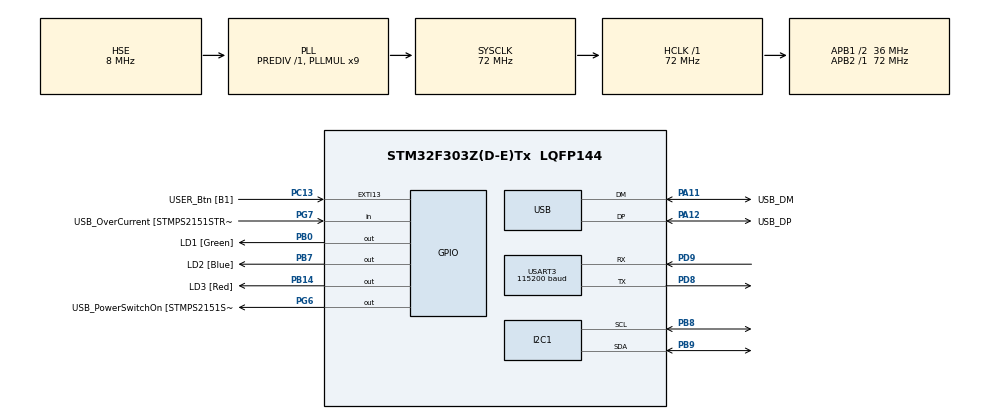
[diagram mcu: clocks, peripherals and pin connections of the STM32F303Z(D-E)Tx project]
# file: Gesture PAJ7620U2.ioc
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Mcu.Family=STM32F3
RCC.CortexFreq_Value=72000000
PG6.Signal=GPIO_Output
PB14.GPIO_Label=LD3 [Red]
PG6.GPIO_Label=USB_PowerSwitchOn [STMPS2151STR_EN]
PA14.GPIO_Label=TCK
RCC.SYSCLKSourceVirtual=RCC_SYSCLKSOURCE_PLLCLK
VP_RTC_VS_RTC_Activate.Mode=RTC_Enabled
PA11.Mode=Device
PB0.GPIO_Label=LD1 [Green]
PC13.GPIO_Label=USER_Btn [B1]
PD9.Mode=Asynchronous
ProjectManager.StackSize=0x400
USART3.VirtualMode-Asynchronous=VM_ASYNC
PA12.Signal=USB_DP
USART3.BaudRate=115200
RCC.HCLKFreq_Value=72000000
RCC.APB2TimFreq_Value=72000000
PD8.Signal=USART3_TX
RCC.AHBFreq_Value=72000000
RCC.HSE_VALUE=8000000
PF0-OSC_IN.GPIO_Label=MCO [STM32F103CBT6_PA8]
RCC.PLLMUL=RCC_PLL_MUL9
PC14-OSC32_IN.Mode=LSE-External-Oscillator
PA14.Mode=Serial_Wire
PB7.Signal=GPIO_Output
PB7.GPIO_Label=LD2 [Blue]
Mcu.Package=LQFP144
PB9.Signal=I2C1_SDA
RCC.APB1TimFreq_Value=72000000
PB3.GPIO_Label=SWO
PC15-OSC32_OUT.Mode=LSE-External-Oscillator
PG7.Signal=GPIO_Input
PC13.Signal=GPXTI13
NVIC.USB_LP_CAN_RX0_IRQn=true\:0\:0\:false\:false\:true\:true\:true
PA11.GPIO_Label=USB_DM
PD9.Signal=USART3_RX
RCC.APB1CLKDivider=RCC_HCLK_DIV2
PC14-OSC32_IN.Signal=RCC_OSC32_IN
PA12.GPIO_Label=USB_DP
PA13.Signal=SYS_JTMS-SWDIO
ProjectManager.TargetToolchain=STM32CubeIDE
PB9.Mode=I2C
RCC.USBFreq_Value=48000000
PC15-OSC32_OUT.Signal=RCC_OSC32_OUT
PD8.Mode=Asynchronous
PF0-OSC_IN.Mode=HSE-External-Clock-Source
PB14.Signal=GPIO_Output
board=NUCLEO-F303ZE
RCC.APB2Freq_Value=72000000
RCC.PRESCALERUSB=RCC_USBCLKSOURCE_PLL_DIV1_5
PG7.GPIO_Label=USB_OverCurrent [STMPS2151STR_FAULT]
PA13.Mode=Serial_Wire
Mcu.Name=STM32F303Z(D-E)Tx
PA13.GPIO_Label=TMS
I2C1.OwnAddress=0x73
PB3.Signal=SYS_JTDO-TRACESWO
RCC.SYSCLKFreq_VALUE=72000000
PA12.Mode=Device
PA11.Signal=USB_DM
PA14.Signal=SYS_JTCK-SWCLK
ProjectManager.HeapSize=0x200
RCC.HSI_VALUE=8000000
NVIC.PriorityGroup=NVIC_PRIORITYGROUP_4
PB8.Mode=I2C
PB8.Signal=I2C1_SCL
PF0-OSC_IN.Signal=RCC_OSC_IN
RCC.APB1Freq_Value=36000000
PB0.Signal=GPIO_Output

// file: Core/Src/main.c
/* USER CODE BEGIN Header */
/**
  ******************************************************************************
  * @file           : main.c
  * @brief          : Main program body
  ******************************************************************************
  * @attention
  *
  * <h2><center>&copy; Copyright (c) 2021 STMicroelectronics.
  * All rights reserved.</center></h2>
  *
  * This software component is licensed by ST under BSD 3-Clause license,
  * the "License"; You may not use this file except in compliance with the
  * License. You may obtain a copy of the License at:
  *                        opensource.org/licenses/BSD-3-Clause
  *
  ******************************************************************************
  */
/* USER CODE END Header */
#include "main.h"

/* USER CODE BEGIN Includes */
#include "GESTURE.h"

/* USER CODE END Includes */

I2C_HandleTypeDef hi2c1;

RTC_HandleTypeDef hrtc;

UART_HandleTypeDef huart3;

PCD_HandleTypeDef hpcd_USB_FS;

void SystemClock_Config(void);
static void MX_GPIO_Init(void);
static void MX_RTC_Init(void);
static void MX_USB_PCD_Init(void);
static void MX_I2C1_Init(void);
static void MX_USART3_UART_Init(void);

int main(void)
{

  /* MCU Configuration--------------------------------------------------------*/

  /* Reset of all peripherals, Initializes the Flash interface and the Systick. */
  HAL_Init();

  /* Configure the system clock */
  SystemClock_Config();

  /* Initialize all configured peripherals */
  MX_GPIO_Init();
  MX_RTC_Init();
  MX_USB_PCD_Init();
  MX_I2C1_Init();
  MX_USART3_UART_Init();

  /* Infinite loop */
  /* USER CODE BEGIN WHILE */
  while (1)
  {
	  /* HAL_Delay(700); */
	 /*  initializeRegisters(); */
	 /*  GESTURE_Actions(); */
    /* USER CODE END WHILE */

    /* USER CODE BEGIN 3 */
	  HAL_Delay(700);
	  GESTURE_Actions();
  }
  /* USER CODE END 3 */
}

void SystemClock_Config(void)
{
  RCC_OscInitTypeDef RCC_OscInitStruct = {0};
  RCC_ClkInitTypeDef RCC_ClkInitStruct = {0};
  RCC_PeriphCLKInitTypeDef PeriphClkInit = {0};

  /** Initializes the RCC Oscillators according to the specified parameters
  * in the RCC_OscInitTypeDef structure.
  */
  RCC_OscInitStruct.OscillatorType = RCC_OSCILLATORTYPE_HSI|RCC_OSCILLATORTYPE_LSI
                              |RCC_OSCILLATORTYPE_HSE;
  RCC_OscInitStruct.HSEState = RCC_HSE_BYPASS;
  RCC_OscInitStruct.HSIState = RCC_HSI_ON;
  RCC_OscInitStruct.HSICalibrationValue = RCC_HSICALIBRATION_DEFAULT;
  RCC_OscInitStruct.LSIState = RCC_LSI_ON;
  RCC_OscInitStruct.PLL.PLLState = RCC_PLL_ON;
  RCC_OscInitStruct.PLL.PLLSource = RCC_PLLSOURCE_HSE;
  RCC_OscInitStruct.PLL.PLLMUL = RCC_PLL_MUL9;
  RCC_OscInitStruct.PLL.PREDIV = RCC_PREDIV_DIV1;
  if (HAL_RCC_OscConfig(&RCC_OscInitStruct) != HAL_OK)
  {
    Error_Handler();
  }
  /** Initializes the CPU, AHB and APB buses clocks
  */
  RCC_ClkInitStruct.ClockType = RCC_CLOCKTYPE_HCLK|RCC_CLOCKTYPE_SYSCLK
                              |RCC_CLOCKTYPE_PCLK1|RCC_CLOCKTYPE_PCLK2;
  RCC_ClkInitStruct.SYSCLKSource = RCC_SYSCLKSOURCE_PLLCLK;
  RCC_ClkInitStruct.AHBCLKDivider = RCC_SYSCLK_DIV1;
  RCC_ClkInitStruct.APB1CLKDivider = RCC_HCLK_DIV2;
  RCC_ClkInitStruct.APB2CLKDivider = RCC_HCLK_DIV1;

  if (HAL_RCC_ClockConfig(&RCC_ClkInitStruct, FLASH_LATENCY_2) != HAL_OK)
  {
    Error_Handler();
  }
  PeriphClkInit.PeriphClockSelection = RCC_PERIPHCLK_USB|RCC_PERIPHCLK_USART3
                              |RCC_PERIPHCLK_I2C1|RCC_PERIPHCLK_RTC;
  PeriphClkInit.Usart3ClockSelection = RCC_USART3CLKSOURCE_PCLK1;
  PeriphClkInit.I2c1ClockSelection = RCC_I2C1CLKSOURCE_HSI;
  PeriphClkInit.RTCClockSelection = RCC_RTCCLKSOURCE_LSI;
  PeriphClkInit.USBClockSelection = RCC_USBCLKSOURCE_PLL_DIV1_5;
  if (HAL_RCCEx_PeriphCLKConfig(&PeriphClkInit) != HAL_OK)
  {
    Error_Handler();
  }
}

static void MX_I2C1_Init(void)
{

  hi2c1.Instance = I2C1;
  hi2c1.Init.Timing = 0x2000090E;
  hi2c1.Init.OwnAddress1 = 230;
  hi2c1.Init.AddressingMode = I2C_ADDRESSINGMODE_7BIT;
  hi2c1.Init.DualAddressMode = I2C_DUALADDRESS_DISABLE;
  hi2c1.Init.OwnAddress2 = 0;
  hi2c1.Init.OwnAddress2Masks = I2C_OA2_NOMASK;
  hi2c1.Init.GeneralCallMode = I2C_GENERALCALL_DISABLE;
  hi2c1.Init.NoStretchMode = I2C_NOSTRETCH_DISABLE;
  if (HAL_I2C_Init(&hi2c1) != HAL_OK)
  {
    Error_Handler();
  }
  /** Configure Analogue filter
  */
  if (HAL_I2CEx_ConfigAnalogFilter(&hi2c1, I2C_ANALOGFILTER_ENABLE) != HAL_OK)
  {
    Error_Handler();
  }
  /** Configure Digital filter
  */
  if (HAL_I2CEx_ConfigDigitalFilter(&hi2c1, 0) != HAL_OK)
  {
    Error_Handler();
  }

}

static void MX_RTC_Init(void)
{

  /** Initialize RTC Only
  */
  hrtc.Instance = RTC;
  hrtc.Init.HourFormat = RTC_HOURFORMAT_24;
  hrtc.Init.AsynchPrediv = 127;
  hrtc.Init.SynchPrediv = 255;
  hrtc.Init.OutPut = RTC_OUTPUT_DISABLE;
  hrtc.Init.OutPutPolarity = RTC_OUTPUT_POLARITY_HIGH;
  hrtc.Init.OutPutType = RTC_OUTPUT_TYPE_OPENDRAIN;
  if (HAL_RTC_Init(&hrtc) != HAL_OK)
  {
    Error_Handler();
  }

}

static void MX_USART3_UART_Init(void)
{

  huart3.Instance = USART3;
  huart3.Init.BaudRate = 115200;
  huart3.Init.WordLength = UART_WORDLENGTH_8B;
  huart3.Init.StopBits = UART_STOPBITS_1;
  huart3.Init.Parity = UART_PARITY_NONE;
  huart3.Init.Mode = UART_MODE_TX_RX;
  huart3.Init.HwFlowCtl = UART_HWCONTROL_NONE;
  huart3.Init.OverSampling = UART_OVERSAMPLING_16;
  huart3.Init.OneBitSampling = UART_ONE_BIT_SAMPLE_DISABLE;
  huart3.AdvancedInit.AdvFeatureInit = UART_ADVFEATURE_NO_INIT;
  if (HAL_UART_Init(&huart3) != HAL_OK)
  {
    Error_Handler();
  }

}

static void MX_USB_PCD_Init(void)
{

  hpcd_USB_FS.Instance = USB;
  hpcd_USB_FS.Init.dev_endpoints = 8;
  hpcd_USB_FS.Init.speed = PCD_SPEED_FULL;
  hpcd_USB_FS.Init.phy_itface = PCD_PHY_EMBEDDED;
  hpcd_USB_FS.Init.low_power_enable = DISABLE;
  hpcd_USB_FS.Init.lpm_enable = DISABLE;
  hpcd_USB_FS.Init.battery_charging_enable = DISABLE;
  if (HAL_PCD_Init(&hpcd_USB_FS) != HAL_OK)
  {
    Error_Handler();
  }

}

static void MX_GPIO_Init(void)
{
  GPIO_InitTypeDef GPIO_InitStruct = {0};

  /* GPIO Ports Clock Enable */
  __HAL_RCC_GPIOC_CLK_ENABLE();
  __HAL_RCC_GPIOF_CLK_ENABLE();
  __HAL_RCC_GPIOB_CLK_ENABLE();
  __HAL_RCC_GPIOD_CLK_ENABLE();
  __HAL_RCC_GPIOG_CLK_ENABLE();
  __HAL_RCC_GPIOA_CLK_ENABLE();

  /*Configure GPIO pin Output Level */
  HAL_GPIO_WritePin(GPIOB, LD1_Pin|LD3_Pin|LD2_Pin, GPIO_PIN_RESET);

  /*Configure GPIO pin Output Level */
  HAL_GPIO_WritePin(USB_PowerSwitchOn_GPIO_Port, USB_PowerSwitchOn_Pin, GPIO_PIN_RESET);

  /*Configure GPIO pin : USER_Btn_Pin */
  GPIO_InitStruct.Pin = USER_Btn_Pin;
  GPIO_InitStruct.Mode = GPIO_MODE_IT_RISING;
  GPIO_InitStruct.Pull = GPIO_NOPULL;
  HAL_GPIO_Init(USER_Btn_GPIO_Port, &GPIO_InitStruct);

  /*Configure GPIO pins : LD1_Pin LD3_Pin LD2_Pin */
  GPIO_InitStruct.Pin = LD1_Pin|LD3_Pin|LD2_Pin;
  GPIO_InitStruct.Mode = GPIO_MODE_OUTPUT_PP;
  GPIO_InitStruct.Pull = GPIO_NOPULL;
  GPIO_InitStruct.Speed = GPIO_SPEED_FREQ_LOW;
  HAL_GPIO_Init(GPIOB, &GPIO_InitStruct);

  /*Configure GPIO pin : USB_PowerSwitchOn_Pin */
  GPIO_InitStruct.Pin = USB_PowerSwitchOn_Pin;
  GPIO_InitStruct.Mode = GPIO_MODE_OUTPUT_PP;
  GPIO_InitStruct.Pull = GPIO_NOPULL;
  GPIO_InitStruct.Speed = GPIO_SPEED_FREQ_LOW;
  HAL_GPIO_Init(USB_PowerSwitchOn_GPIO_Port, &GPIO_InitStruct);

  /*Configure GPIO pin : USB_OverCurrent_Pin */
  GPIO_InitStruct.Pin = USB_OverCurrent_Pin;
  GPIO_InitStruct.Mode = GPIO_MODE_INPUT;
  GPIO_InitStruct.Pull = GPIO_NOPULL;
  HAL_GPIO_Init(USB_OverCurrent_GPIO_Port, &GPIO_InitStruct);

}

void Error_Handler(void)
{
  __disable_irq();
  while (1)
  {
  }
}

/************************ (C) COPYRIGHT STMicroelectronics *****END OF FILE****/
